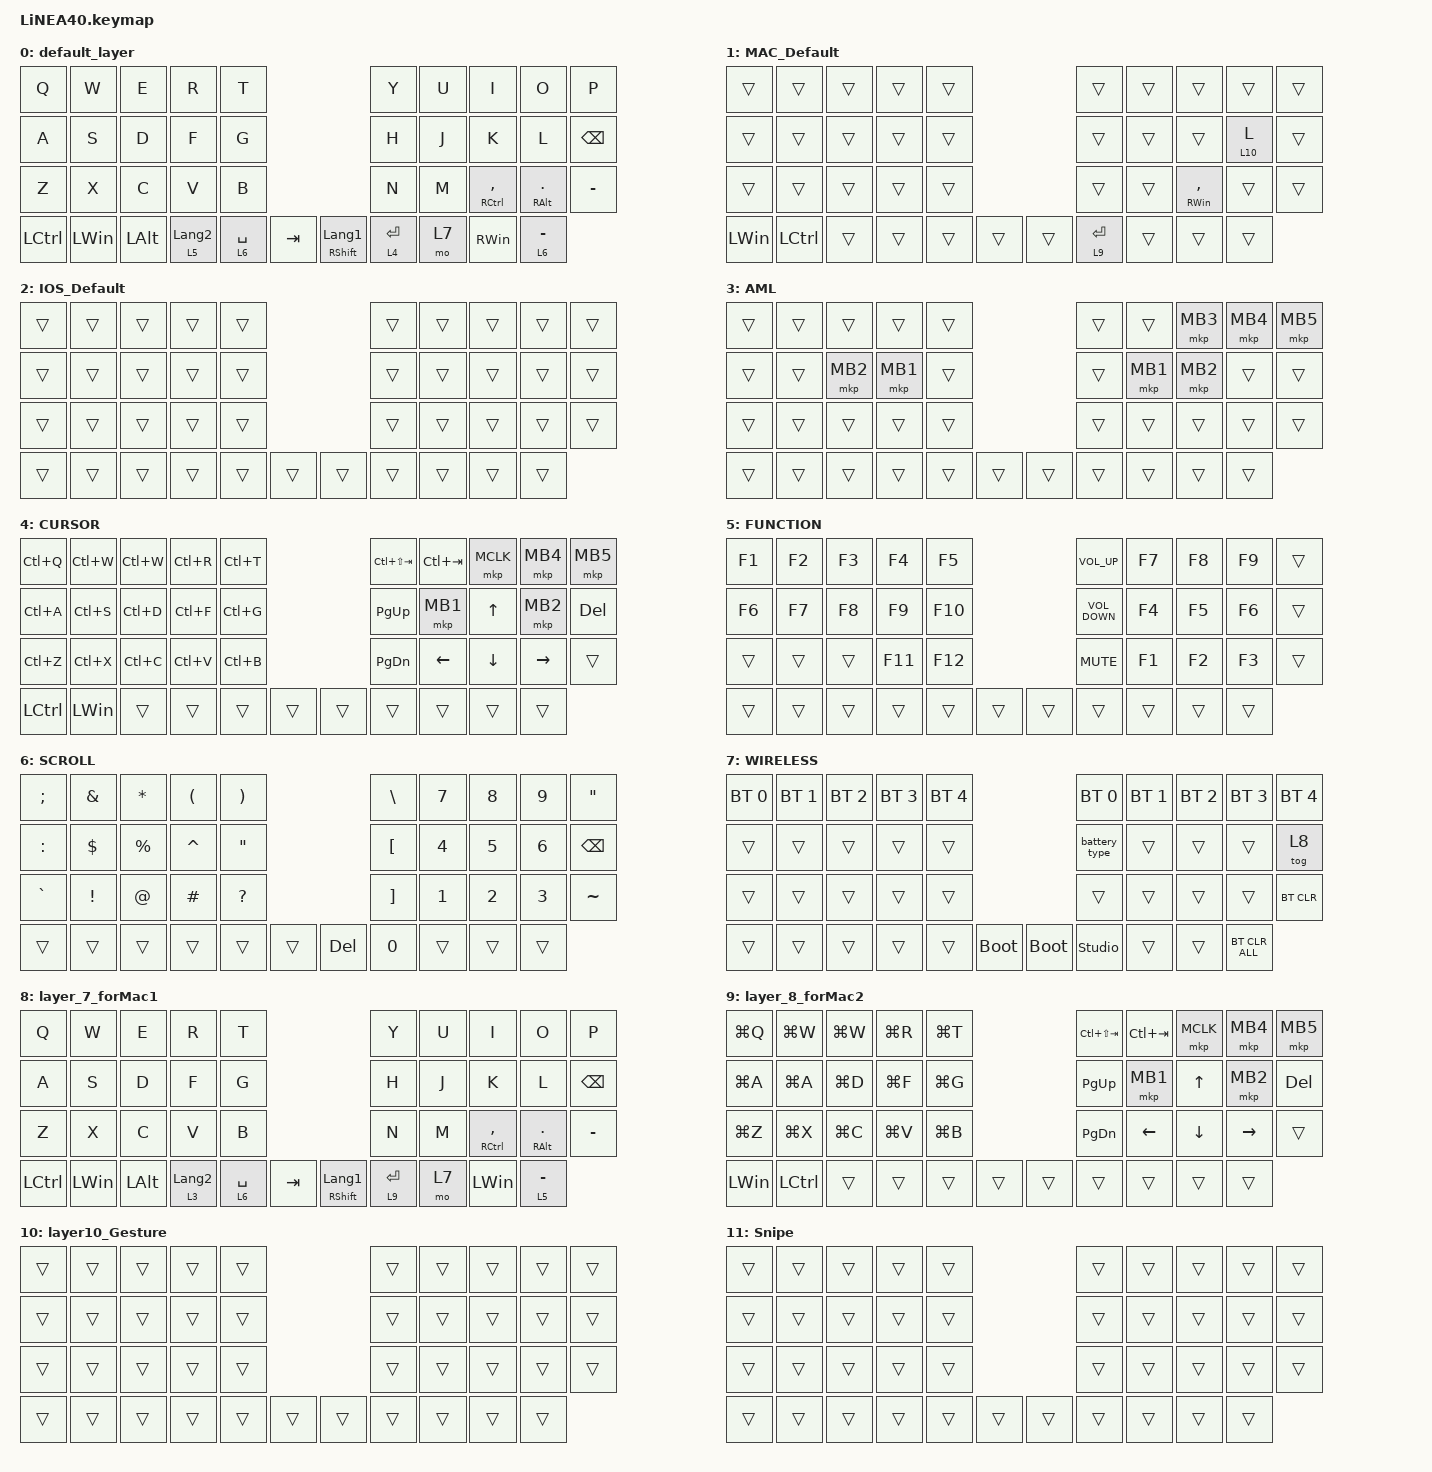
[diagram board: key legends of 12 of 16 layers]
#define ZMK_POINTING_DEFAULT_SCRL_VAL 150

#include <dt-bindings/zmk/input_transform.h>
#include <input/processors.dtsi>
#include <zephyr/dt-bindings/input/input-event-codes.h>
#include <mouse-gesture.dtsi>
#include <behaviors.dtsi>
#include <dt-bindings/zmk/bt.h>
#include <dt-bindings/zmk/keys.h>
#include <dt-bindings/zmk/pointing.h>

#define MOUSE 1
#define MARK 2
#define CURSOR 3
#define FUNCTION 4
#define SCROLL 5
#define WIRELESS 6

// --- JIS(日本語配列)エイリアス ---
// ZMKコアは JP_* を定義しないためローカル定義（eswai/zmk_mable 準拠）。
// A-3: JISホスト側で US層と同じグリフを出すHID usageに写像する（JIS_SYMBOLS 層で使用）。
// 素キー（JISで別グリフになる usage）
#define JP_AT    LBKT          // @  (0x2F)
#define JP_LBKT  RBKT          // [  (0x30)
#define JP_RBKT  NUHS          // ]  (0x32)
#define JP_COLON SQT           // :  (0x34)
#define JP_CARET EQUAL         // ^  (0x2E)
#define JP_BSLH  INT1          // \  (0x87)  ※pos5用。実打不出なら JP_YEN(INT3) 代替を検討
// シフト合成
#define JP_AMPS  LS(N6)        // &
#define JP_ASTRK LS(JP_COLON)  // *
#define JP_LPAR  LS(N8)        // (
#define JP_RPAR  LS(N9)        // )
#define JP_DQT   LS(N2)        // "
#define JP_GRAVE LS(JP_AT)     // `
#define JP_TILDE LS(JP_CARET)  // ~
// #define JP_YEN INT3         // ¥/\  (0x89)  ※ホスト依存の代替（§2.3※）

//mouse cursol

&mmv {
    delay-ms = <20>;
    trigger-period-ms = <5>;
    time-to-max-speed-ms = <100>;
    acceleration-exponent = <2>;
};

//mouse scroll

&msc {
    delay-ms = <3>;
    trigger-period-ms = <3>;
    time-to-max-speed-ms = <100>;
    acceleration-exponent = <0>;
};

/ {
    input_processors {
        zip_wheel_scaler: zip_wheel_scaler {
            compatible = "zmk,input-processor-scaler";
            #input-processor-cells = <2>;
            type = <INPUT_EV_REL>;
            codes = <INPUT_REL_WHEEL>;
            track-remainders;
        };
    };
};

&msc_input_listener {
    speed_up {
        layers = <FUNCTION>;
        input-processors = <&zip_wheel_scaler 3 1>; //スクロールを3倍速にする
    };
};

&trackball_listener {
    scroller {
        layers = <SCROLL>;
        input-processors =
            <&zip_xy_transform INPUT_TRANSFORM_Y_INVERT>,
            //スクロール方向を逆転,,,,,,,,,,,,,,,,,,,,,,,,,,,,
            <&zip_xy_to_scroll_mapper>;
    };

    gesture {
        layers = <10>;
        input-processors = <&zip_mouse_gesture>;
    };
};

&zip_mouse_gesture {
    always-active;
    enable-eager-mode;
    stroke-size = <200>;

    prev_desktop {
        pattern = <GESTURE_LEFT>;
        bindings = <&kp LC(LEFT_ARROW)>;
    };

    next_desktop {
        pattern = <GESTURE_RIGHT>;
        bindings = <&kp LC(RIGHT_ARROW)>;
    };

    mission_control {
        pattern = <GESTURE_UP>;
        bindings = <&kp LC(UP_ARROW)>;
    };

    launchpad {
        pattern = <GESTURE_DOWN>;
        bindings = <&kp LS(LG(A))>;
    };
};

/ {
    battery_type: battery_type {
        compatible = "zmk,behavior-battery-type";
        #binding-cells = <0>;
    };

    usb_fp_type: usb_fp_type {
        compatible = "zmk,behavior-usb-fp-type";
        #binding-cells = <0>;
    };

    combos {
        compatible = "zmk,combos";

        equal {
            bindings = <&kp EQUAL>;
            key-positions = <26 27>;
            layers = <6 15>;
        };

        dot {
            bindings = <&kp PERIOD>;
            key-positions = <27 28>;
            layers = <6 15>;
        };

        minus {
            bindings = <&kp MINUS>;
            key-positions = <16 17>;
            layers = <6 15>;
        };

        plus {
            bindings = <&kp PLUS>;
            key-positions = <17 18>;
            layers = <6 15>;
        };

        slash {
            bindings = <&kp SLASH>;
            key-positions = <7 6>;
            layers = <6 15>;
        };

        Asterisk {
            bindings = <&kp ASTERISK>;
            key-positions = <7 8>;
            layers = <6 15>;
        };

        lang1 {
            bindings = <&kp LANGUAGE_1>;
            key-positions = <15 16>;
            layers = <0>;
        };

        lang2 {
            bindings = <&kp LANGUAGE_2>;
            key-positions = <13 14>;
            layers = <0>;
        };

        leftclick2 {
            bindings = <&mkp MB1>;
            key-positions = <12 13>;
            layers = <0 3>;
        };

        Rightclick2 {
            bindings = <&mkp MB2>;
            key-positions = <11 12>;
            layers = <0 3>;
        };

        middleclick2 {
            bindings = <&mkp MB3>;
            key-positions = <12 11 13>;
            layers = <0 3>;
        };

        combo_esc {
            bindings = <&kp ESCAPE>;
            key-positions = <0 1>;
            layers = <0 1 2 14>;
        };

        combo_tab {
            bindings = <&kp TAB>;
            key-positions = <10 10 11>;
            layers = <0>;
        };

        combo_shift {
            bindings = <&kp LSHIFT>;
            key-positions = <20 21>;
            layers = <0 1 2 14>;
        };

        leftclick3 {
            bindings = <&mkp MB1>;
            key-positions = <17 16>;
            layers = <0 3>;
        };

        combo_F10 {
            bindings = <&kp F10>;
            key-positions = <26 16>;
            layers = <5 3>;
        };

        combo_F11 {
            bindings = <&kp F11>;
            key-positions = <17 27>;
            layers = <5 3>;
        };

        combo_F12 {
            bindings = <&kp F12>;
            key-positions = <18 28>;
            layers = <5 3>;
        };

        combo_Scroll {
            bindings = <&mo 6>;
            key-positions = <9 8>;
            layers = <0 1 2 14>;
        };
    };

    behaviors {
        re_kp: sensor_rotate_kp {
            compatible = "zmk,behavior-sensor-rotate-var";
            #sensor-binding-cells = <2>;
            bindings = <&kp>, <&kp>;
        };

        mouse_scrl: mouse_wheel_scrl {
            compatible = "zmk,behavior-sensor-rotate-var";
            #sensor-binding-cells = <2>;
            bindings = <&msc>, <&msc>;

            tap-ms = <20>;
        };
    };

    keymap {
        compatible = "zmk,keymap";

        default_layer {
            bindings = <
&kp Q      &kp W         &kp E         &kp R             &kp T                                               &kp Y        &kp U  &kp I            &kp O                 &kp P
&kp A      &kp S         &kp D         &kp F             &kp G                                               &kp H        &kp J  &kp K            &kp L                 &kp BACKSPACE
&kp Z      &kp X         &kp C         &kp V             &kp B                                               &kp N        &kp M  &mt RCTRL COMMA  &mt RIGHT_ALT PERIOD  &kp MINUS
&kp LCTRL  &kp LEFT_WIN  &kp LEFT_ALT  &lt 5 LANGUAGE_2  &lt 6 SPACE  &kp TAB    &mt RIGHT_SHIFT LANGUAGE_1  &lt 4 ENTER         &mo 7            &kp RIGHT_WIN         &lt 6 MINUS
            >;

            sensor-bindings = <&mouse_scrl SCRL_DOWN SCRL_UP>;
        };

        MAC_Default {
            bindings = <
&trans        &trans     &trans  &trans  &trans                    &trans       &trans  &trans               &trans    &trans
&trans        &trans     &trans  &trans  &trans                    &trans       &trans  &trans               &lt 10 L  &trans
&trans        &trans     &trans  &trans  &trans                    &trans       &trans  &mt RIGHT_WIN COMMA  &trans    &trans
&kp LEFT_WIN  &kp LCTRL  &trans  &trans  &trans  &trans    &trans  &lt 9 ENTER          &trans               &trans    &trans
            >;
        };

        IOS_Default {
            bindings = <
&trans  &trans  &trans  &trans  &trans                    &trans  &trans  &trans  &trans  &trans
&trans  &trans  &trans  &trans  &trans                    &trans  &trans  &trans  &trans  &trans
&trans  &trans  &trans  &trans  &trans                    &trans  &trans  &trans  &trans  &trans
&trans  &trans  &trans  &trans  &trans  &trans    &trans  &trans          &trans  &trans  &trans
            >;
        };

        AML {
            bindings = <
&trans  &trans  &trans    &trans    &trans                    &trans  &trans    &mkp MB3  &mkp MB4  &mkp MB5
&trans  &trans  &mkp MB2  &mkp MB1  &trans                    &trans  &mkp MB1  &mkp MB2  &trans    &trans
&trans  &trans  &trans    &trans    &trans                    &trans  &trans    &trans    &trans    &trans
&trans  &trans  &trans    &trans    &trans  &trans    &trans  &trans            &trans    &trans    &trans
            >;

            sensor-bindings = <&mouse_scrl SCRL_DOWN SCRL_UP>;
        };

        CURSOR {
            bindings = <
&kp LC(Q)  &kp LC(W)     &kp LC(W)  &kp LC(R)  &kp LC(T)                    &kp LC(LS(TAB))  &kp LC(TAB)     &mkp MCLK       &mkp MB4         &mkp MB5
&kp LC(A)  &kp LC(S)     &kp LC(D)  &kp LC(F)  &kp LC(G)                    &kp PAGE_UP      &mkp MB1        &kp UP_ARROW    &mkp MB2         &kp DEL
&kp LC(Z)  &kp LC(X)     &kp LC(C)  &kp LC(V)  &kp LC(B)                    &kp PAGE_DOWN    &kp LEFT_ARROW  &kp DOWN_ARROW  &kp RIGHT_ARROW  &trans
&kp LCTRL  &kp LEFT_WIN  &trans     &trans     &trans     &trans    &trans  &trans                           &trans          &trans           &trans
            >;

            sensor-bindings = <&inc_dec_kp C_VOLUME_DOWN C_VOLUME_UP>;
        };

        FUNCTION {
            bindings = <
&kp F1  &kp F2  &kp F3  &kp F4   &kp F5                     &kp C_VOLUME_UP    &kp F7  &kp F8  &kp F9  &trans
&kp F6  &kp F7  &kp F8  &kp F9   &kp F10                    &kp C_VOLUME_DOWN  &kp F4  &kp F5  &kp F6  &trans
&trans  &trans  &trans  &kp F11  &kp F12                    &kp C_MUTE         &kp F1  &kp F2  &kp F3  &trans
&trans  &trans  &trans  &trans   &trans   &trans    &trans  &trans                     &trans  &trans  &trans
            >;

            sensor-bindings = <&mouse_scrl SCRL_DOWN SCRL_UP>;
        };

        SCROLL {
            bindings = <
&kp SEMICOLON  &kp AMPERSAND    &kp ASTERISK  &kp LEFT_PARENTHESIS  &kp RIGHT_PARENTHESIS                     &kp BACKSLASH  &kp NUMBER_7  &kp NUMBER_8  &kp NUMBER_9  &kp DQT
&kp COLON      &kp DOLLAR       &kp PERCENT   &kp CARET             &kp DOUBLE_QUOTES                         &kp LBKT       &kp NUMBER_4  &kp NUMBER_5  &kp NUMBER_6  &kp BACKSPACE
&kp GRAVE      &kp EXCLAMATION  &kp AT_SIGN   &kp POUND             &kp QUESTION                              &kp RBKT       &kp NUMBER_1  &kp NUMBER_2  &kp NUMBER_3  &kp TILDE
&trans         &trans           &trans        &trans                &trans                 &trans    &kp DEL  &kp NUMBER_0                 &trans        &trans        &trans
            >;

            sensor-bindings = <&inc_dec_kp DOWN_ARROW UP_ARROW>;
        };

        WIRELESS {
            bindings = <
&bt BT_SEL 0  &bt BT_SEL 1  &bt BT_SEL 2  &bt BT_SEL 3  &bt BT_SEL 4                              &bt BT_SEL 0    &bt BT_SEL 1  &bt BT_SEL 2  &bt BT_SEL 3  &bt BT_SEL 4
&trans        &trans        &trans        &trans        &trans                                    &battery_type   &trans        &trans        &trans        &tog 8
&trans        &trans        &trans        &trans        &trans                                    &trans          &trans        &trans        &trans        &bt BT_CLR
&trans        &trans        &trans        &trans        &trans        &bootloader    &bootloader  &studio_unlock                &trans        &trans        &bt BT_CLR_ALL
            >;

            sensor-bindings = <&inc_dec_kp RIGHT_ARROW LEFT_ARROW>;
        };

        layer_7_forMac1 {
            bindings = <
&kp Q      &kp W         &kp E         &kp R             &kp T                                               &kp Y        &kp U  &kp I            &kp O                 &kp P
&kp A      &kp S         &kp D         &kp F             &kp G                                               &kp H        &kp J  &kp K            &kp L                 &kp BACKSPACE
&kp Z      &kp X         &kp C         &kp V             &kp B                                               &kp N        &kp M  &mt RCTRL COMMA  &mt RIGHT_ALT PERIOD  &kp MINUS
&kp LCTRL  &kp LEFT_WIN  &kp LEFT_ALT  &lt 3 LANGUAGE_2  &lt 6 SPACE  &kp TAB    &mt RIGHT_SHIFT LANGUAGE_1  &lt 9 ENTER         &mo 7            &kp LEFT_WIN          &lt 5 MINUS
            >;

            sensor-bindings = <&mouse_scrl SCRL_DOWN SCRL_UP>;
        };

        layer_8_forMac2 {
            bindings = <
&kp LG(Q)     &kp LG(W)  &kp LG(W)  &kp LG(R)  &kp LG(T)                    &kp LC(LS(TAB))  &kp LC(TAB)     &mkp MCLK       &mkp MB4         &mkp MB5
&kp LG(A)     &kp LG(A)  &kp LG(D)  &kp LG(F)  &kp LG(G)                    &kp PAGE_UP      &mkp MB1        &kp UP_ARROW    &mkp MB2         &kp DEL
&kp LG(Z)     &kp LG(X)  &kp LG(C)  &kp LG(V)  &kp LG(B)                    &kp PAGE_DOWN    &kp LEFT_ARROW  &kp DOWN_ARROW  &kp RIGHT_ARROW  &trans
&kp LEFT_WIN  &kp LCTRL  &trans     &trans     &trans     &trans    &trans  &trans                           &trans          &trans           &trans
            >;

            sensor-bindings = <&inc_dec_kp C_VOLUME_DOWN C_VOLUME_UP>;
        };

        layer10_Gesture {
            bindings = <
&trans  &trans  &trans  &trans  &trans                    &trans  &trans  &trans  &trans  &trans
&trans  &trans  &trans  &trans  &trans                    &trans  &trans  &trans  &trans  &trans
&trans  &trans  &trans  &trans  &trans                    &trans  &trans  &trans  &trans  &trans
&trans  &trans  &trans  &trans  &trans  &trans    &trans  &trans          &trans  &trans  &trans
            >;
        };

        spare_layer_1 {
            display-name = "Snipe";
            bindings = <
&trans  &trans  &trans  &trans  &trans                    &trans  &trans  &trans  &trans  &trans
&trans  &trans  &trans  &trans  &trans                    &trans  &trans  &trans  &trans  &trans
&trans  &trans  &trans  &trans  &trans                    &trans  &trans  &trans  &trans  &trans
&trans  &trans  &trans  &trans  &trans  &trans    &trans  &trans          &trans  &trans  &trans
            >;
        };

        spare_layer_2 {
            display-name = "Spare 2";
            bindings = <
&trans  &trans  &trans  &trans  &trans                    &trans  &trans  &trans  &trans  &trans
&trans  &trans  &trans  &trans  &trans                    &trans  &trans  &trans  &trans  &trans
&trans  &trans  &trans  &trans  &trans                    &trans  &trans  &trans  &trans  &trans
&trans  &trans  &trans  &trans  &trans  &trans    &trans  &trans          &trans  &trans  &trans
            >;
        };

        spare_layer_3 {
            display-name = "Spare 3";
            bindings = <
&trans  &trans  &trans  &trans  &trans                    &trans  &trans  &trans  &trans  &trans
&trans  &trans  &trans  &trans  &trans                    &trans  &trans  &trans  &trans  &trans
&trans  &trans  &trans  &trans  &trans                    &trans  &trans  &trans  &trans  &trans
&trans  &trans  &trans  &trans  &trans  &trans    &trans  &trans          &trans  &trans  &trans
            >;
        };

        JIS_MODE {
            // 実index 14: 全&transのモードフラグ層（打鍵には影響しない）。
            // behavior_os_layer.c が profile_is_jis[] に従い activate/deactivate する。
            display-name = "JIS Mode";
            bindings = <
&trans  &trans  &trans  &trans  &trans                    &trans  &trans  &trans  &trans  &trans
&trans  &trans  &trans  &trans  &trans                    &trans  &trans  &trans  &trans  &trans
&trans  &trans  &trans  &trans  &trans                    &trans  &trans  &trans  &trans  &trans
&trans  &trans  &trans  &trans  &trans  &trans    &trans  &trans          &trans  &trans  &trans
            >;
        };

        JIS_SYMBOLS {
            // 実index 15: SCROLL(6)へのJIS差分オーバーレイ。&trans はSCROLL(6)へフォールバック。
            // conditional_layers で SCROLL(6)+JIS_MODE(14) 同時Active時のみ有効化される。
            display-name = "JIS Sym";
            bindings = <
&trans        &kp JP_AMPS   &kp JP_ASTRK  &kp JP_LPAR   &kp JP_RPAR                       &kp JP_BSLH   &trans  &trans  &trans  &kp JP_DQT
&kp JP_COLON  &trans        &trans        &kp JP_CARET  &kp JP_DQT                        &kp JP_LBKT   &trans  &trans  &trans  &trans
&kp JP_GRAVE  &trans        &kp JP_AT     &trans        &trans                            &kp JP_RBKT   &trans  &trans  &trans  &kp JP_TILDE
&trans        &trans        &trans        &trans        &trans        &trans    &trans    &trans                &trans  &trans  &trans
            >;
        };
    };

    conditional_layers {
        compatible = "zmk,conditional-layers";

        jis_symbols {
            // SCROLL(実6) と JIS_MODE(14) が同時Active → JIS_SYMBOLS(15) を有効化。
            // ★生の数値。#define SCROLL(=5) は実indexと不一致なので使わない。
            if-layers = <6 14>;
            then-layer = <15>;
        };
    };
};
